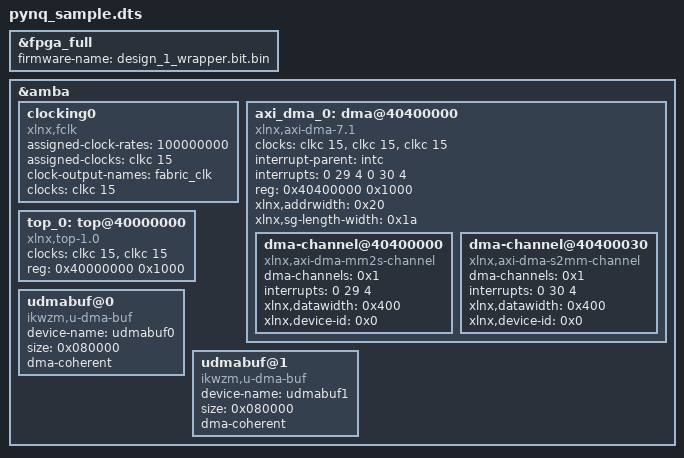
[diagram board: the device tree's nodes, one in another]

/*
 * CAUTION: This file is automatically generated by Xilinx.
 * Version: XSCT 2022.1
 * Today is: Wed Oct 19 00:26:17 2022
 */


/dts-v1/;
/plugin/;
/ {
	fragment@0 {
		target = <&fpga_full>;
		overlay0: __overlay__ {
			#address-cells = <2>;
			#size-cells = <2>;
			firmware-name = "design_1_wrapper.bit.bin";
		};
	};
	fragment@1 {
		target = <&amba>;
		overlay1: __overlay__ {
			clocking0: clocking0 {
				#clock-cells = <0>;
				assigned-clock-rates = <100000000>;
				assigned-clocks = <&clkc 15>;
				clock-output-names = "fabric_clk";
				clocks = <&clkc 15>;
				compatible = "xlnx,fclk";
			};
		};
	};
	fragment@2 {
		target = <&amba>;
		overlay2: __overlay__ {
			#address-cells = <1>;
			#size-cells = <1>;
			axi_dma_0: dma@40400000 {
				#dma-cells = <1>;
				clock-names = "s_axi_lite_aclk", "m_axi_mm2s_aclk", "m_axi_s2mm_aclk";
				clocks = <&clkc 15>, <&clkc 15>, <&clkc 15>;
				compatible = "xlnx,axi-dma-7.1", "xlnx,axi-dma-1.00.a";
				interrupt-names = "mm2s_introut", "s2mm_introut";
				interrupt-parent = <&intc>;
				interrupts = <0 29 4 0 30 4>;
				reg = <0x40400000 0x1000>;
				xlnx,addrwidth = <0x20>;
				xlnx,sg-length-width = <0x1a>;
				dma-channel@40400000 {
					compatible = "xlnx,axi-dma-mm2s-channel";
					dma-channels = <0x1>;
					interrupts = <0 29 4>;
					xlnx,datawidth = <0x400>;
					xlnx,device-id = <0x0>;
				};
				dma-channel@40400030 {
					compatible = "xlnx,axi-dma-s2mm-channel";
					dma-channels = <0x1>;
					interrupts = <0 30 4>;
					xlnx,datawidth = <0x400>;
					xlnx,device-id = <0x0>;
				};
			};
			top_0: top@40000000 {
				/* This is a place holder node for a custom IP, user may need to update the entries */
				clock-names = "S_AXI_ACLK", "AXIS_ACLK";
				clocks = <&clkc 15>, <&clkc 15>;
				compatible = "xlnx,top-1.0";
				reg = <0x40000000 0x1000>;
			};
            udmabuf@0 {
                compatible = "ikwzm,u-dma-buf";
                device-name = "udmabuf0";
                size = <0x080000>; // 512KB
		        dma-coherent;
            };

            udmabuf@1 {
                compatible = "ikwzm,u-dma-buf";
		        device-name = "udmabuf1";
                size = <0x080000>; // 512KB
		        dma-coherent;
            };
		};
	};
};

